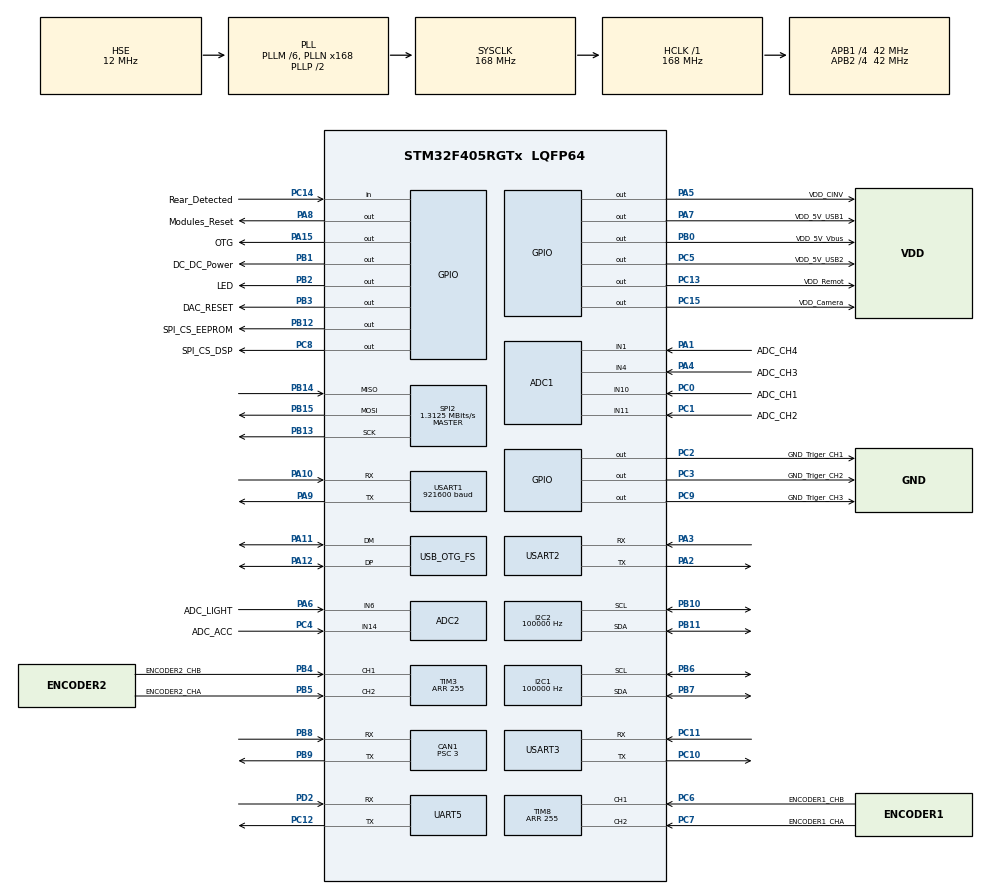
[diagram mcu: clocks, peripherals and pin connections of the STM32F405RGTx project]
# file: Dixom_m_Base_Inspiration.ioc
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ADC1.Channel-0\#ChannelRegularConversion=ADC_CHANNEL_10
ADC1.Channel-1\#ChannelRegularConversion=ADC_CHANNEL_11
ADC1.Channel-2\#ChannelRegularConversion=ADC_CHANNEL_4
ADC1.Channel-3\#ChannelRegularConversion=ADC_CHANNEL_1
ADC1.ClockPrescaler=ADC_CLOCK_SYNC_PCLK_DIV8
ADC1.ContinuousConvMode=ENABLE
ADC1.DMAContinuousRequests=ENABLE
ADC1.NbrOfConversion=4
ADC1.NbrOfConversionFlag=1
ADC1.Rank-0\#ChannelRegularConversion=1
ADC1.Rank-1\#ChannelRegularConversion=2
ADC1.Rank-2\#ChannelRegularConversion=3
ADC1.Rank-3\#ChannelRegularConversion=4
ADC1.SamplingTime-0\#ChannelRegularConversion=ADC_SAMPLETIME_3CYCLES
ADC1.SamplingTime-1\#ChannelRegularConversion=ADC_SAMPLETIME_3CYCLES
ADC1.SamplingTime-2\#ChannelRegularConversion=ADC_SAMPLETIME_3CYCLES
ADC1.SamplingTime-3\#ChannelRegularConversion=ADC_SAMPLETIME_3CYCLES
ADC1.ScanConvMode=ENABLE
ADC1.master=1
ADC2.Channel-1\#ChannelRegularConversion=ADC_CHANNEL_14
ADC2.Channel-2\#ChannelRegularConversion=ADC_CHANNEL_6
ADC2.ClockPrescaler=ADC_CLOCK_SYNC_PCLK_DIV8
ADC2.ContinuousConvMode=ENABLE
ADC2.DMAContinuousRequests=ENABLE
ADC2.NbrOfConversion=2
ADC2.NbrOfConversionFlag=1
ADC2.Rank-1\#ChannelRegularConversion=1
ADC2.Rank-2\#ChannelRegularConversion=2
ADC2.SamplingTime-1\#ChannelRegularConversion=ADC_SAMPLETIME_3CYCLES
ADC2.SamplingTime-2\#ChannelRegularConversion=ADC_SAMPLETIME_3CYCLES
ADC2.ScanConvMode=ENABLE
CAN1.BS1=CAN_BS1_11TQ
CAN1.BS2=CAN_BS2_2TQ
CAN1.CalculateBaudRate=1000000
CAN1.CalculateTimeBit=1000
CAN1.CalculateTimeQuantum=71.42857142857143
CAN1.Prescaler=3
CAN1.SJW=CAN_SJW_2TQ
Dma.ADC1.0.Direction=DMA_PERIPH_TO_MEMORY
Dma.ADC1.0.FIFOMode=DMA_FIFOMODE_ENABLE
Dma.ADC1.0.FIFOThreshold=DMA_FIFO_THRESHOLD_HALFFULL
Dma.ADC1.0.Instance=DMA2_Stream0
Dma.ADC1.0.MemBurst=DMA_MBURST_SINGLE
Dma.ADC1.0.MemDataAlignment=DMA_MDATAALIGN_HALFWORD
Dma.ADC1.0.MemInc=DMA_MINC_ENABLE
Dma.ADC1.0.Mode=DMA_CIRCULAR
Dma.ADC1.0.PeriphBurst=DMA_PBURST_SINGLE
Dma.ADC1.0.PeriphDataAlignment=DMA_PDATAALIGN_HALFWORD
Dma.ADC1.0.PeriphInc=DMA_PINC_DISABLE
Dma.ADC1.0.Priority=DMA_PRIORITY_LOW
Dma.ADC2.1.Direction=DMA_PERIPH_TO_MEMORY
Dma.ADC2.1.FIFOMode=DMA_FIFOMODE_ENABLE
Dma.ADC2.1.FIFOThreshold=DMA_FIFO_THRESHOLD_HALFFULL
Dma.ADC2.1.Instance=DMA2_Stream2
Dma.ADC2.1.MemBurst=DMA_MBURST_SINGLE
Dma.ADC2.1.MemDataAlignment=DMA_MDATAALIGN_HALFWORD
Dma.ADC2.1.MemInc=DMA_MINC_ENABLE
Dma.ADC2.1.Mode=DMA_CIRCULAR
Dma.ADC2.1.PeriphBurst=DMA_PBURST_SINGLE
Dma.ADC2.1.PeriphDataAlignment=DMA_PDATAALIGN_HALFWORD
Dma.ADC2.1.PeriphInc=DMA_PINC_DISABLE
Dma.ADC2.1.Priority=DMA_PRIORITY_LOW
Dma.I2C1_TX.4.Direction=DMA_MEMORY_TO_PERIPH
Dma.I2C1_TX.4.FIFOMode=DMA_FIFOMODE_DISABLE
Dma.I2C1_TX.4.Instance=DMA1_Stream6
Dma.I2C1_TX.4.MemDataAlignment=DMA_MDATAALIGN_BYTE
Dma.I2C1_TX.4.MemInc=DMA_MINC_ENABLE
Dma.I2C1_TX.4.Mode=DMA_NORMAL
Dma.I2C1_TX.4.PeriphDataAlignment=DMA_PDATAALIGN_BYTE
Dma.I2C1_TX.4.PeriphInc=DMA_PINC_DISABLE
Dma.I2C1_TX.4.Priority=DMA_PRIORITY_LOW
Dma.I2C2_RX.6.Direction=DMA_PERIPH_TO_MEMORY
Dma.I2C2_RX.6.FIFOMode=DMA_FIFOMODE_DISABLE
Dma.I2C2_RX.6.Instance=DMA1_Stream2
Dma.I2C2_RX.6.MemDataAlignment=DMA_MDATAALIGN_BYTE
Dma.I2C2_RX.6.MemInc=DMA_MINC_ENABLE
Dma.I2C2_RX.6.Mode=DMA_NORMAL
Dma.I2C2_RX.6.PeriphDataAlignment=DMA_PDATAALIGN_BYTE
Dma.I2C2_RX.6.PeriphInc=DMA_PINC_DISABLE
Dma.I2C2_RX.6.Priority=DMA_PRIORITY_LOW
Dma.I2C2_TX.5.Direction=DMA_MEMORY_TO_PERIPH
Dma.I2C2_TX.5.FIFOMode=DMA_FIFOMODE_DISABLE
Dma.I2C2_TX.5.Instance=DMA1_Stream7
Dma.I2C2_TX.5.MemDataAlignment=DMA_MDATAALIGN_BYTE
Dma.I2C2_TX.5.MemInc=DMA_MINC_ENABLE
Dma.I2C2_TX.5.Mode=DMA_NORMAL
Dma.I2C2_TX.5.PeriphDataAlignment=DMA_PDATAALIGN_BYTE
Dma.I2C2_TX.5.PeriphInc=DMA_PINC_DISABLE
Dma.I2C2_TX.5.Priority=DMA_PRIORITY_LOW
Dma.Request0=ADC1
Dma.Request1=ADC2
Dma.Request2=USART1_TX
Dma.Request3=USART1_RX
Dma.Request4=I2C1_TX
Dma.Request5=I2C2_TX
Dma.Request6=I2C2_RX
Dma.USART1_RX.3.Direction=DMA_PERIPH_TO_MEMORY
Dma.USART1_RX.3.FIFOMode=DMA_FIFOMODE_DISABLE
Dma.USART1_RX.3.Instance=DMA2_Stream5
Dma.USART1_RX.3.MemDataAlignment=DMA_MDATAALIGN_BYTE
Dma.USART1_RX.3.MemInc=DMA_MINC_ENABLE
Dma.USART1_RX.3.Mode=DMA_NORMAL
Dma.USART1_RX.3.PeriphDataAlignment=DMA_PDATAALIGN_BYTE
Dma.USART1_RX.3.PeriphInc=DMA_PINC_DISABLE
Dma.USART1_RX.3.Priority=DMA_PRIORITY_LOW
Dma.USART1_TX.2.Direction=DMA_MEMORY_TO_PERIPH
Dma.USART1_TX.2.FIFOMode=DMA_FIFOMODE_DISABLE
Dma.USART1_TX.2.Instance=DMA2_Stream7
Dma.USART1_TX.2.MemDataAlignment=DMA_MDATAALIGN_BYTE
Dma.USART1_TX.2.MemInc=DMA_MINC_ENABLE
Dma.USART1_TX.2.Mode=DMA_NORMAL
Dma.USART1_TX.2.PeriphDataAlignment=DMA_PDATAALIGN_BYTE
Dma.USART1_TX.2.PeriphInc=DMA_PINC_DISABLE
Dma.USART1_TX.2.Priority=DMA_PRIORITY_LOW
FREERTOS.BinarySemaphores01=BinarySem_ExchangeI2C2,Dynamic,NULL;BinarySem_ExchangeI2C1,Dynamic,NULL;BinarySem_ExchangeSPI2,Dynamic,NULL;BinarySem_TxUSB_HID,Dynamic,NULL;BinarySem_TxUART1,Dynamic,NULL;BinarySem_TxUSB_CDC,Dynamic,NULL;BinarySem_DataOut,Dynamic,NULL
FREERTOS.Queues01=SendUsb,16,uint16_t,0,Dynamic,NULL,NULL;NewMessageFromUsb,16,uint16_t,0,Dynamic,NULL,NULL
FREERTOS.Tasks01=Main_Task,0,640,Start_Control_Task,Default,NULL,Dynamic,NULL,NULL;UART_RESIVE,-3,512,Start_UART_RESIVE,Default,NULL,Dynamic,NULL,NULL;LED_STROB,-3,512,Start_LED_STROB,Default,NULL,Dynamic,NULL,NULL;SendDataUsb,-3,640,Start_SendDataUsb,Default,NULL,Dynamic,NULL,NULL;Display,-3,512,Start_Display,Default,NULL,Dynamic,NULL,NULL;Interaction,-3,640,Start_Interaction,Default,NULL,Dynamic,NULL,NULL
FREERTOS.configENABLE_BACKWARD_COMPATIBILITY=0
FREERTOS.configRECORD_STACK_HIGH_ADDRESS=1
FREERTOS.configTOTAL_HEAP_SIZE=32768
FREERTOS.configUSE_NEWLIB_REENTRANT=1
I2C1.ClockSpeed=100000
I2C1.I2C_Mode=I2C_Fast
I2C2.ClockSpeed=100000
I2C2.I2C_Mode=I2C_Fast
IWDG.Prescaler=IWDG_PRESCALER_256
Mcu.Family=STM32F4
Mcu.Name=STM32F405RGTx
Mcu.Package=LQFP64
NVIC.CAN1_RX0_IRQn=true\:5\:0\:false\:false\:true\:true\:true\:true\:true
NVIC.CAN1_RX1_IRQn=true\:5\:0\:false\:false\:true\:true\:true\:true\:true
NVIC.CAN1_SCE_IRQn=true\:5\:0\:false\:false\:true\:true\:true\:true\:true
NVIC.CAN1_TX_IRQn=true\:5\:0\:false\:false\:true\:true\:true\:true\:true
NVIC.DMA1_Stream2_IRQn=true\:5\:0\:false\:false\:true\:true\:false\:true\:true
NVIC.DMA1_Stream6_IRQn=true\:5\:0\:false\:false\:true\:true\:false\:true\:true
NVIC.DMA1_Stream7_IRQn=true\:5\:0\:false\:false\:true\:true\:false\:true\:true
NVIC.DMA2_Stream0_IRQn=true\:5\:0\:false\:false\:true\:true\:false\:true\:true
NVIC.DMA2_Stream2_IRQn=true\:5\:0\:false\:false\:true\:true\:false\:true\:true
NVIC.DMA2_Stream5_IRQn=true\:5\:0\:false\:false\:true\:true\:false\:true\:true
NVIC.DMA2_Stream7_IRQn=true\:5\:0\:false\:false\:true\:true\:false\:true\:true
NVIC.I2C2_ER_IRQn=true\:5\:0\:false\:false\:true\:true\:true\:true\:true
NVIC.I2C2_EV_IRQn=true\:5\:0\:false\:false\:true\:true\:true\:true\:true
NVIC.OTG_FS_IRQn=true\:5\:0\:false\:false\:true\:true\:true\:true\:true
NVIC.PriorityGroup=NVIC_PRIORITYGROUP_4
NVIC.TIM3_IRQn=true\:5\:0\:false\:false\:true\:true\:true\:true\:true
NVIC.TIM6_DAC_IRQn=true\:5\:0\:false\:false\:true\:true\:true\:true\:true
NVIC.TIM7_IRQn=true\:5\:0\:false\:false\:true\:true\:true\:true\:true
NVIC.UART5_IRQn=true\:5\:0\:false\:false\:true\:true\:true\:true\:true
NVIC.USART1_IRQn=true\:5\:0\:false\:false\:true\:true\:true\:true\:true
NVIC.USART3_IRQn=true\:5\:0\:false\:false\:true\:true\:true\:true\:true
PA0-WKUP.GPIO_Label=WakeUP
PA0-WKUP.Mode=SYS_WakeUp0
PA0-WKUP.Signal=SYS_WKUP
PA1.GPIO_Label=ADC_CH4
PA1.Signal=ADCx_IN1
PA10.Mode=Asynchronous
PA10.Signal=USART1_RX
PA11.Mode=Device_Only
PA11.Signal=USB_OTG_FS_DM
PA12.Mode=Device_Only
PA12.Signal=USB_OTG_FS_DP
PA13.Mode=Serial_Wire
PA13.Signal=SYS_JTMS-SWDIO
PA14.Mode=Serial_Wire
PA14.Signal=SYS_JTCK-SWCLK
PA15.GPIO_Label=OTG
PA15.PinState=GPIO_PIN_SET
PA15.Signal=GPIO_Output
PA2.Mode=Asynchronous
PA2.Signal=USART2_TX
PA3.Mode=Asynchronous
PA3.Signal=USART2_RX
PA4.GPIO_Label=ADC_CH3
PA4.Signal=ADCx_IN4
PA5.GPIO_Label=VDD_CINV
PA5.Signal=GPIO_Output
PA6.GPIO_Label=ADC_LIGHT
PA6.Signal=ADCx_IN6
PA7.GPIO_Label=VDD_5V_USB1
PA7.Signal=GPIO_Output
PA8.GPIO_Label=Modules_Reset
PA8.Signal=GPIO_Output
PA9.Mode=Asynchronous
PA9.Signal=USART1_TX
PB0.GPIO_Label=VDD_5V_Vbus
PB0.Signal=GPIO_Output
PB1.GPIO_Label=DC_DC_Power
PB1.Signal=GPIO_Output
PB10.Mode=I2C
PB10.Signal=I2C2_SCL
PB11.Mode=I2C
PB11.Signal=I2C2_SDA
PB12.GPIO_Label=SPI_CS_EEPROM
PB12.Signal=GPIO_Output
PB13.Mode=Full_Duplex_Master
PB13.Signal=SPI2_SCK
PB14.Mode=Full_Duplex_Master
PB14.Signal=SPI2_MISO
PB15.Mode=Full_Duplex_Master
PB15.Signal=SPI2_MOSI
PB2.GPIO_Label=LED
PB2.Signal=GPIO_Output
PB3.GPIO_Label=DAC_RESET
PB3.Signal=GPIO_Output
PB4.GPIO_Label=ENCODER2_CHB
PB4.Signal=S_TIM3_CH1
PB5.GPIO_Label=ENCODER2_CHA
PB5.Signal=S_TIM3_CH2
PB6.Mode=I2C
PB6.Signal=I2C1_SCL
PB7.Mode=I2C
PB7.Signal=I2C1_SDA
PB8.Mode=CAN_Activate
PB8.Signal=CAN1_RX
PB9.Mode=CAN_Activate
PB9.Signal=CAN1_TX
PC0.GPIO_Label=ADC_CH1
PC0.Signal=ADCx_IN10
PC1.GPIO_Label=ADC_CH2
PC1.Signal=ADCx_IN11
PC10.Mode=Asynchronous
PC10.Signal=USART3_TX
PC11.Mode=Asynchronous
PC11.Signal=USART3_RX
PC12.Mode=Asynchronous
PC12.Signal=UART5_TX
PC13-ANTI_TAMP.GPIO_Label=VDD_Remot
PC13-ANTI_TAMP.Signal=GPIO_Output
PC14-OSC32_IN.GPIO_Label=Rear_Detected
PC14-OSC32_IN.Signal=GPIO_Input
PC15-OSC32_OUT.GPIO_Label=VDD_Camera
PC15-OSC32_OUT.Signal=GPIO_Output
PC2.GPIO_Label=GND_Triger_CH1
PC2.Signal=GPIO_Output
PC3.GPIO_Label=GND_Triger_CH2
PC3.Signal=GPIO_Output
PC4.GPIO_Label=ADC_ACC
PC4.Signal=ADCx_IN14
PC5.GPIO_Label=VDD_5V_USB2
PC5.Signal=GPIO_Output
PC6.GPIO_Label=ENCODER1_CHB
PC6.Signal=S_TIM8_CH1
PC7.GPIO_Label=ENCODER1_CHA
PC7.Signal=S_TIM8_CH2
PC8.GPIO_Label=SPI_CS_DSP
PC8.Signal=GPIO_Output
PC9.GPIO_Label=GND_Triger_CH3
PC9.Signal=GPIO_Output
PD2.Mode=Asynchronous
PD2.Signal=UART5_RX
PH0-OSC_IN.Mode=HSE-External-Oscillator
PH0-OSC_IN.Signal=RCC_OSC_IN
PH1-OSC_OUT.Mode=HSE-External-Oscillator
PH1-OSC_OUT.Signal=RCC_OSC_OUT
ProjectManager.HeapSize=0x200
ProjectManager.StackSize=0x400
ProjectManager.TargetToolchain=STM32CubeIDE
RCC.48MHZClocksFreq_Value=48000000
RCC.AHBFreq_Value=168000000
RCC.APB1CLKDivider=RCC_HCLK_DIV4
RCC.APB1Freq_Value=42000000
RCC.APB1TimFreq_Value=84000000
RCC.APB2CLKDivider=RCC_HCLK_DIV4
RCC.APB2Freq_Value=42000000
RCC.APB2TimFreq_Value=84000000
RCC.CortexFreq_Value=168000000
RCC.HCLKFreq_Value=168000000
RCC.HSE_VALUE=12000000
RCC.HSI_VALUE=16000000
RCC.LSE_VALUE=32768
RCC.PLLM=6
RCC.PLLN=168
RCC.PLLQ=7
RCC.SYSCLKFreq_VALUE=168000000
RCC.SYSCLKSource=RCC_SYSCLKSOURCE_PLLCLK
RCC.VCOOutputFreq_Value=336000000
SH.ADCx_IN1.0=ADC1_IN1,IN1
SH.ADCx_IN10.0=ADC1_IN10,IN10
SH.ADCx_IN11.0=ADC1_IN11,IN11
SH.ADCx_IN14.0=ADC2_IN14,IN14
SH.ADCx_IN4.0=ADC1_IN4,IN4
SH.ADCx_IN6.0=ADC2_IN6,IN6
SH.S_TIM3_CH1.0=TIM3_CH1,Encoder_Interface
SH.S_TIM3_CH2.0=TIM3_CH2,Encoder_Interface
SH.S_TIM8_CH1.0=TIM8_CH1,Encoder_Interface
SH.S_TIM8_CH2.0=TIM8_CH2,Encoder_Interface
SPI2.BaudRatePrescaler=SPI_BAUDRATEPRESCALER_32
SPI2.CalculateBaudRate=1.3125 MBits/s
SPI2.Direction=SPI_DIRECTION_2LINES
SPI2.Mode=SPI_MODE_MASTER
SPI2.VirtualType=VM_MASTER
TIM3.Period=255
TIM6.Period=1
TIM6.Prescaler=50000
TIM6.TIM_MasterOutputTrigger=TIM_TRGO_UPDATE
TIM7.Period=1
TIM7.Prescaler=50000
TIM7.TIM_MasterOutputTrigger=TIM_TRGO_UPDATE
TIM8.Period=255
UART5.VirtualMode=Asynchronous
USART1.BaudRate=921600
USART1.VirtualMode=VM_ASYNC
USART2.VirtualMode=VM_ASYNC
USART3.VirtualMode=VM_ASYNC
USB_OTG_FS.VirtualMode=Device_Only
VP_CRC_VS_CRC.Mode=CRC_Activate
VP_FREERTOS_VS_CMSIS_V1.Mode=CMSIS_V1
VP_IWDG_VS_IWDG.Mode=IWDG_Activate
VP_TIM6_VS_ClockSourceINT.Mode=Enable_Timer
VP_TIM7_VS_ClockSourceINT.Mode=Enable_Timer
board=custom

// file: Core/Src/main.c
/* USER CODE BEGIN Header */
/**
  ******************************************************************************
  * @file           : main.c
  * @brief          : Main program body
  ******************************************************************************
  * @attention
  *
  * Copyright (c) 2023 STMicroelectronics.
  * All rights reserved.
  *
  * This software is licensed under terms that can be found in the LICENSE file
  * in the root directory of this software component.
  * If no LICENSE file comes with this software, it is provided AS-IS.
  *
  ******************************************************************************
  */
/* USER CODE END Header */
#include "main.h"
#include "cmsis_os.h"
#include "adc.h"
#include "can.h"
#include "crc.h"
#include "dma.h"
#include "i2c.h"
#include "iwdg.h"
#include "spi.h"
#include "tim.h"
#include "usart.h"
#include "usb_otg.h"
#include "gpio.h"

/* USER CODE BEGIN Includes */
#include "Structures.h"
/* USER CODE END Includes */

void SystemClock_Config(void);
void MX_FREERTOS_Init(void);

int main(void)
{

  /* USER CODE BEGIN 1 */
  /*
   *           !!!!!!!!NECESSARILY!!!!!!!!
   * Attention. After generating code in CUBE MX.
   * 1 - MX_GPIO_Init(); put before SystemClock_Config();
   * 2 - comment out // MX_IWDG_Init();
   *
   */
  //Disable interrupts
  __disable_irq();
  //move the beginning of the interrupt vector to the specified address
  SCB->VTOR = MAIN_APLICATION_ADDR;
  //Enable interrupts
  __enable_irq();
  /* USER CODE END 1 */

  /* MCU Configuration--------------------------------------------------------*/

  /* Reset of all peripherals, Initializes the Flash interface and the Systick. */
  HAL_Init();

  /* Configure the system clock */
  SystemClock_Config();

  /* Initialize all configured peripherals */
  MX_GPIO_Init();
  MX_DMA_Init();
  MX_ADC1_Init();
  MX_ADC2_Init();
  MX_USB_OTG_FS_PCD_Init();
  //MX_IWDG_Init();
  MX_TIM3_Init();
  MX_TIM6_Init();
  MX_TIM8_Init();
  MX_CAN1_Init();
  MX_I2C1_Init();
  MX_I2C2_Init();
  MX_SPI2_Init();
  MX_UART5_Init();
  MX_USART1_UART_Init();
  MX_CRC_Init();
  MX_USART2_UART_Init();
  MX_USART3_UART_Init();
  MX_TIM7_Init();

  /* Call init function for freertos objects (in cmsis_os2.c) */
  MX_FREERTOS_Init();

  /* Start scheduler */
  osKernelStart();

  /* We should never get here as control is now taken by the scheduler */

  /* Infinite loop */
  while (1)
  {

  }
}

void SystemClock_Config(void)
{
  RCC_OscInitTypeDef RCC_OscInitStruct = {0};
  RCC_ClkInitTypeDef RCC_ClkInitStruct = {0};

  /** Configure the main internal regulator output voltage
  */
  __HAL_RCC_PWR_CLK_ENABLE();
  __HAL_PWR_VOLTAGESCALING_CONFIG(PWR_REGULATOR_VOLTAGE_SCALE1);

  /** Initializes the RCC Oscillators according to the specified parameters
  * in the RCC_OscInitTypeDef structure.
  */
  RCC_OscInitStruct.OscillatorType = RCC_OSCILLATORTYPE_LSI|RCC_OSCILLATORTYPE_HSE;
  RCC_OscInitStruct.HSEState = RCC_HSE_ON;
  RCC_OscInitStruct.LSIState = RCC_LSI_ON;
  RCC_OscInitStruct.PLL.PLLState = RCC_PLL_ON;
  RCC_OscInitStruct.PLL.PLLSource = RCC_PLLSOURCE_HSE;
  RCC_OscInitStruct.PLL.PLLM = 6;
  RCC_OscInitStruct.PLL.PLLN = 168;
  RCC_OscInitStruct.PLL.PLLP = RCC_PLLP_DIV2;
  RCC_OscInitStruct.PLL.PLLQ = 7;
  if (HAL_RCC_OscConfig(&RCC_OscInitStruct) != HAL_OK)
  {
    Error_Handler();
  }

  /** Initializes the CPU, AHB and APB buses clocks
  */
  RCC_ClkInitStruct.ClockType = RCC_CLOCKTYPE_HCLK|RCC_CLOCKTYPE_SYSCLK
                              |RCC_CLOCKTYPE_PCLK1|RCC_CLOCKTYPE_PCLK2;
  RCC_ClkInitStruct.SYSCLKSource = RCC_SYSCLKSOURCE_PLLCLK;
  RCC_ClkInitStruct.AHBCLKDivider = RCC_SYSCLK_DIV1;
  RCC_ClkInitStruct.APB1CLKDivider = RCC_HCLK_DIV4;
  RCC_ClkInitStruct.APB2CLKDivider = RCC_HCLK_DIV4;

  if (HAL_RCC_ClockConfig(&RCC_ClkInitStruct, FLASH_LATENCY_5) != HAL_OK)
  {
    Error_Handler();
  }
}

void Error_Handler(void)
{
  __disable_irq();
  while (1)
  {
  }
}

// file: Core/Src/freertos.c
/* USER CODE BEGIN Header */
/**
  ******************************************************************************
  * File Name          : freertos.c
  * Description        : Code for freertos applications
  ******************************************************************************
  * @attention
  *
  * Copyright (c) 2023 STMicroelectronics.
  * All rights reserved.
  *
  * This software is licensed under terms that can be found in the LICENSE file
  * in the root directory of this software component.
  * If no LICENSE file comes with this software, it is provided AS-IS.
  *
  ******************************************************************************
  */
/* USER CODE END Header */

#include "FreeRTOS.h"
#include "task.h"
#include "main.h"
#include "cmsis_os.h"

/* USER CODE BEGIN Includes */
#include "usb_device.h"
/* USER CODE END Includes */

osThreadId Main_TaskHandle;
osThreadId UART_RESIVEHandle;
osThreadId LED_STROBHandle;
osThreadId SendDataUsbHandle;
osThreadId DisplayHandle;
osThreadId InteractionHandle;
osMessageQId SendUsbHandle;
osMessageQId NewMessageFromUsbHandle;
osSemaphoreId BinarySem_ExchangeI2C2Handle;
osSemaphoreId BinarySem_ExchangeI2C1Handle;
osSemaphoreId BinarySem_ExchangeSPI2Handle;
osSemaphoreId BinarySem_TxUSB_HIDHandle;
osSemaphoreId BinarySem_TxUART1Handle;
osSemaphoreId BinarySem_TxUSB_CDCHandle;
osSemaphoreId BinarySem_DataOutHandle;

void Start_Control_Task(void const * argument);
void Start_UART_RESIVE(void const * argument);
void Start_LED_STROB(void const * argument);
void Start_SendDataUsb(void const * argument);
void Start_Display(void const * argument);
void Start_Interaction(void const * argument);

void MX_FREERTOS_Init(void); /* (MISRA C 2004 rule 8.1) */

/* GetIdleTaskMemory prototype (linked to static allocation support) */
void vApplicationGetIdleTaskMemory( StaticTask_t **ppxIdleTaskTCBBuffer, StackType_t **ppxIdleTaskStackBuffer, uint32_t *pulIdleTaskStackSize );

/* USER CODE BEGIN GET_IDLE_TASK_MEMORY */
static StaticTask_t xIdleTaskTCBBuffer;
static StackType_t xIdleStack[configMINIMAL_STACK_SIZE];

void vApplicationGetIdleTaskMemory( StaticTask_t **ppxIdleTaskTCBBuffer, StackType_t **ppxIdleTaskStackBuffer, uint32_t *pulIdleTaskStackSize )
{
  *ppxIdleTaskTCBBuffer = &xIdleTaskTCBBuffer;
  *ppxIdleTaskStackBuffer = &xIdleStack[0];
  *pulIdleTaskStackSize = configMINIMAL_STACK_SIZE;
  /* place for user code */
}
/* USER CODE END GET_IDLE_TASK_MEMORY */

void MX_FREERTOS_Init(void) {

  /* Create the semaphores(s) */
  /* definition and creation of BinarySem_ExchangeI2C2 */
  osSemaphoreDef(BinarySem_ExchangeI2C2);
  BinarySem_ExchangeI2C2Handle = osSemaphoreCreate(osSemaphore(BinarySem_ExchangeI2C2), 1);

  /* definition and creation of BinarySem_ExchangeI2C1 */
  osSemaphoreDef(BinarySem_ExchangeI2C1);
  BinarySem_ExchangeI2C1Handle = osSemaphoreCreate(osSemaphore(BinarySem_ExchangeI2C1), 1);

  /* definition and creation of BinarySem_ExchangeSPI2 */
  osSemaphoreDef(BinarySem_ExchangeSPI2);
  BinarySem_ExchangeSPI2Handle = osSemaphoreCreate(osSemaphore(BinarySem_ExchangeSPI2), 1);

  /* definition and creation of BinarySem_TxUSB_HID */
  osSemaphoreDef(BinarySem_TxUSB_HID);
  BinarySem_TxUSB_HIDHandle = osSemaphoreCreate(osSemaphore(BinarySem_TxUSB_HID), 1);

  /* definition and creation of BinarySem_TxUART1 */
  osSemaphoreDef(BinarySem_TxUART1);
  BinarySem_TxUART1Handle = osSemaphoreCreate(osSemaphore(BinarySem_TxUART1), 1);

  /* definition and creation of BinarySem_TxUSB_CDC */
  osSemaphoreDef(BinarySem_TxUSB_CDC);
  BinarySem_TxUSB_CDCHandle = osSemaphoreCreate(osSemaphore(BinarySem_TxUSB_CDC), 1);

  /* definition and creation of BinarySem_DataOut */
  osSemaphoreDef(BinarySem_DataOut);
  BinarySem_DataOutHandle = osSemaphoreCreate(osSemaphore(BinarySem_DataOut), 1);

  /* Create the queue(s) */
  /* definition and creation of SendUsb */
  osMessageQDef(SendUsb, 16, uint16_t);
  SendUsbHandle = osMessageCreate(osMessageQ(SendUsb), NULL);

  /* definition and creation of NewMessageFromUsb */
  osMessageQDef(NewMessageFromUsb, 16, uint16_t);
  NewMessageFromUsbHandle = osMessageCreate(osMessageQ(NewMessageFromUsb), NULL);

  /* Create the thread(s) */
  /* definition and creation of Main_Task */
  osThreadDef(Main_Task, Start_Control_Task, osPriorityNormal, 0, 640);
  Main_TaskHandle = osThreadCreate(osThread(Main_Task), NULL);

  /* definition and creation of UART_RESIVE */
  osThreadDef(UART_RESIVE, Start_UART_RESIVE, osPriorityIdle, 0, 512);
  UART_RESIVEHandle = osThreadCreate(osThread(UART_RESIVE), NULL);

  /* definition and creation of LED_STROB */
  osThreadDef(LED_STROB, Start_LED_STROB, osPriorityIdle, 0, 512);
  LED_STROBHandle = osThreadCreate(osThread(LED_STROB), NULL);

  /* definition and creation of SendDataUsb */
  osThreadDef(SendDataUsb, Start_SendDataUsb, osPriorityIdle, 0, 640);
  SendDataUsbHandle = osThreadCreate(osThread(SendDataUsb), NULL);

  /* definition and creation of Display */
  osThreadDef(Display, Start_Display, osPriorityIdle, 0, 512);
  DisplayHandle = osThreadCreate(osThread(Display), NULL);

  /* definition and creation of Interaction */
  osThreadDef(Interaction, Start_Interaction, osPriorityIdle, 0, 640);
  InteractionHandle = osThreadCreate(osThread(Interaction), NULL);

}

void Start_Control_Task(void const * argument)
{
  /* USER CODE BEGIN Start_Control_Task */
	Task_Main_Setup();
	MX_USB_DEVICE_Init();
  /* Infinite loop */
  for(;;)
  {
	Task_Main_Infinite_Loop();
    osDelay(1);
  }
  /* USER CODE END Start_Control_Task */
}

void Start_UART_RESIVE(void const * argument)
{
  /* USER CODE BEGIN Start_UART_RESIVE */
  /* Infinite loop */
  for(;;)
  {
    Task_Execution_With_Time_Interval();
    osDelay(1);
  }
  /* USER CODE END Start_UART_RESIVE */
}

void Start_LED_STROB(void const * argument)
{
  /* USER CODE BEGIN Start_LED_STROB */
  /* Infinite loop */
  for(;;)
  {
	Task_Flashing_LED_Indicator_Infinite_Loop();
    osDelay(1);
  }
  /* USER CODE END Start_LED_STROB */
}

void Start_SendDataUsb(void const * argument)
{
  /* USER CODE BEGIN Start_SendDataUsb */

  /* Infinite loop */
  for(;;)
  {
	Task_Perifer_Service_Infinite_Loop();
    osDelay(1);
  }
  /* USER CODE END Start_SendDataUsb */
}

void Start_Display(void const * argument)
{
  /* USER CODE BEGIN Start_Display */
  /* Infinite loop */
  for(;;)
  {
	Task_Display_Infinite_Loop();
    osDelay(1);
  }
  /* USER CODE END Start_Display */
}

void Start_Interaction(void const * argument)
{
  /* USER CODE BEGIN Start_Interaction */
  /* Infinite loop */
  for(;;)
  {
	Task_Interaction_Infinite_Loop();
    osDelay(1);
  }
  /* USER CODE END Start_Interaction */
}
